# PIC32MX274F256B register map
Registers are 32-bit, access not given, reset 0x0 unless marked. A register's access mark holds for its fields unless they carry their own. Offsets are from the block's base; [hi:lo] are bit positions; 'fields as' and 'values as' point back to an identical list.

## CVR — CVR peripheral
Base 0xBF809800
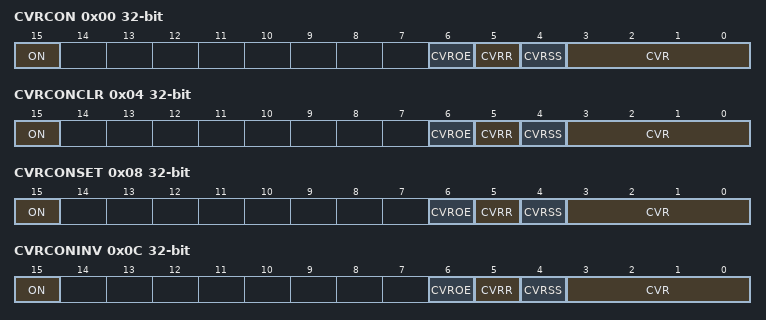
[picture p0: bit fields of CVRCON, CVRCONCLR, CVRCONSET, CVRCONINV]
0x00 CVRCON
  [15] ON, [6] CVROE, [5] CVRR, [4] CVRSS, [3:0] CVR
0x04 CVRCONCLR
  [15] ON, [6] CVROE, [5] CVRR, [4] CVRSS, [3:0] CVR
0x08 CVRCONSET
  [15] ON, [6] CVROE, [5] CVRR, [4] CVRSS, [3:0] CVR
0x0C CVRCONINV
  [15] ON, [6] CVROE, [5] CVRR, [4] CVRSS, [3:0] CVR

## CMP1 — CMP1 peripheral
Base 0xBF80A000
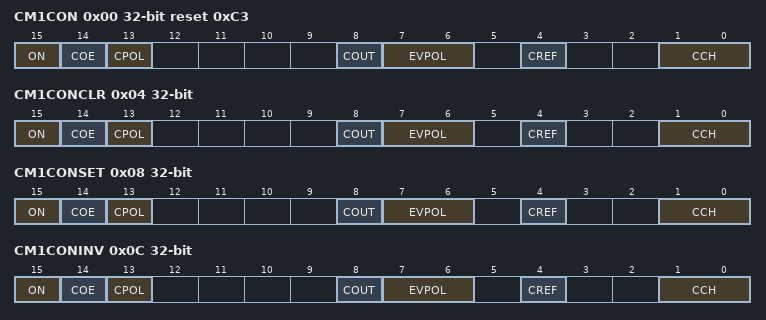
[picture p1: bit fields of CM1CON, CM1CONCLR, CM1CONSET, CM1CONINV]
0x00 CM1CON reset 0xC3
  [15] ON, [14] COE, [13] CPOL, [8] COUT, [7:6] EVPOL, [4] CREF, [1:0] CCH
0x04 CM1CONCLR
  fields as CM1CON
0x08 CM1CONSET
  fields as CM1CON
0x0C CM1CONINV
  fields as CM1CON

## CMP2 — CMP2 peripheral
Base 0xBF80A010
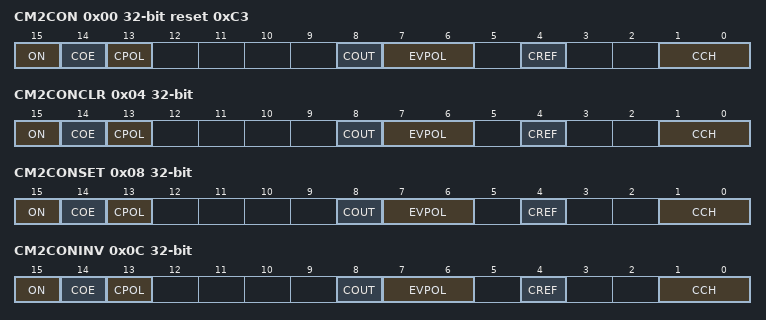
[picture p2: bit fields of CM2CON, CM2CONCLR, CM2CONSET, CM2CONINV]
0x00 CM2CON reset 0xC3
  [15] ON, [14] COE, [13] CPOL, [8] COUT, [7:6] EVPOL, [4] CREF, [1:0] CCH
0x04 CM2CONCLR
  fields as CM2CON
0x08 CM2CONSET
  fields as CM2CON
0x0C CM2CONINV
  fields as CM2CON

## CMP3 — CMP3 peripheral
Base 0xBF80A020
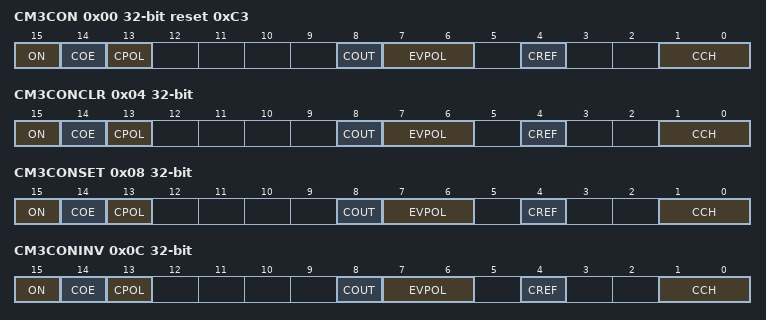
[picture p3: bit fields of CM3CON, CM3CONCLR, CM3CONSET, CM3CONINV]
0x00 CM3CON reset 0xC3
  [15] ON, [14] COE, [13] CPOL, [8] COUT, [7:6] EVPOL, [4] CREF, [1:0] CCH
0x04 CM3CONCLR
  fields as CM3CON
0x08 CM3CONSET
  fields as CM3CON
0x0C CM3CONINV
  fields as CM3CON

## CMP — CMP peripheral
Base 0xBF80A060
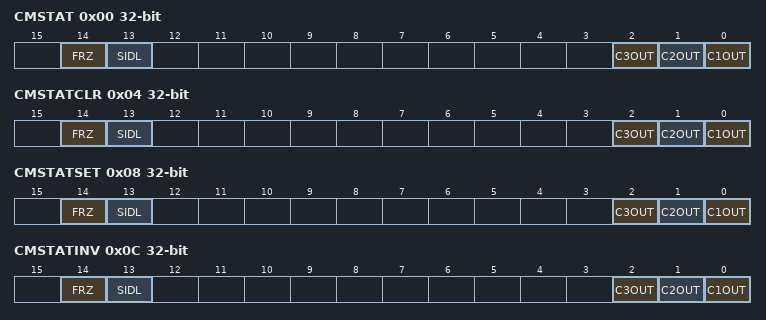
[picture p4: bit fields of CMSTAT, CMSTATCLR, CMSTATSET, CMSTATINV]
0x00 CMSTAT
  [14] FRZ, [13] SIDL, [2] C3OUT, [1] C2OUT, [0] C1OUT
0x04 CMSTATCLR
  [14] FRZ, [13] SIDL, [2] C3OUT, [1] C2OUT, [0] C1OUT
0x08 CMSTATSET
  [14] FRZ, [13] SIDL, [2] C3OUT, [1] C2OUT, [0] C1OUT
0x0C CMSTATINV
  [14] FRZ, [13] SIDL, [2] C3OUT, [1] C2OUT, [0] C1OUT

## CTMU — CTMU peripheral
Base 0xBF80A200
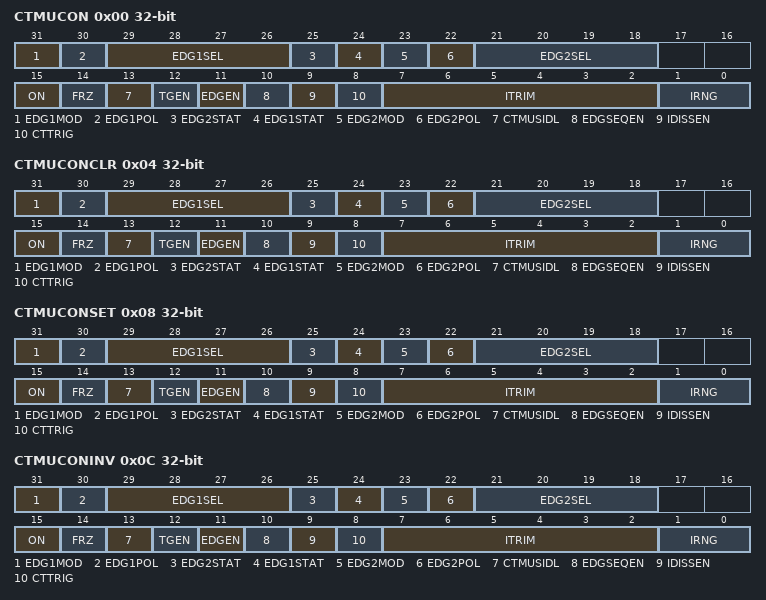
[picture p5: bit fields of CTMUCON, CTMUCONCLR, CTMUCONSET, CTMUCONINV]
0x00 CTMUCON
  [31] EDG1MOD, [30] EDG1POL, [29:26] EDG1SEL, [25] EDG2STAT, [24] EDG1STAT, [23] EDG2MOD, [22] EDG2POL, [21:18] EDG2SEL, [15] ON, [14] FRZ, [13] CTMUSIDL, [12] TGEN, [11] EDGEN, [10] EDGSEQEN, [9] IDISSEN, [8] CTTRIG, [7:2] ITRIM, [1:0] IRNG
0x04 CTMUCONCLR
  fields as CTMUCON
0x08 CTMUCONSET
  fields as CTMUCON
0x0C CTMUCONINV
  fields as CTMUCON

## CRU — CRU peripheral
Base 0xBF80F000
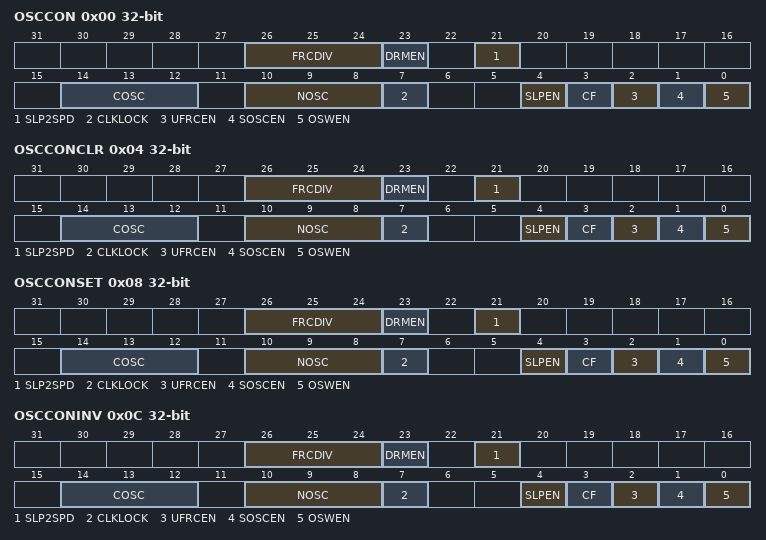
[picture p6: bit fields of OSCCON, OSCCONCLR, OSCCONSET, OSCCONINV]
0x00 OSCCON
  [26:24] FRCDIV, [23] DRMEN, [21] SLP2SPD, [14:12] COSC, [10:8] NOSC, [7] CLKLOCK, [4] SLPEN, [3] CF, [2] UFRCEN, [1] SOSCEN, [0] OSWEN
0x04 OSCCONCLR
  fields as OSCCON
0x08 OSCCONSET
  fields as OSCCON
0x0C OSCCONINV
  fields as OSCCON
0x10 OSCTUN
  [5:0] TUN
0x14 OSCTUNCLR
  [5:0] TUN
0x18 OSCTUNSET
  [5:0] TUN
0x1C OSCTUNINV
  [5:0] TUN
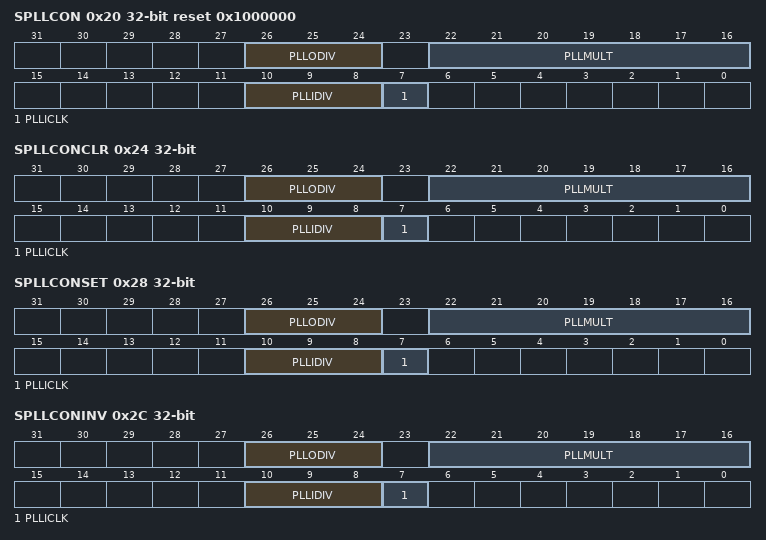
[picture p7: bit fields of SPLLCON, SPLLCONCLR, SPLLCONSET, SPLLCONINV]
0x20 SPLLCON reset 0x1000000
  [26:24] PLLODIV, [22:16] PLLMULT, [10:8] PLLIDIV, [7] PLLICLK
0x24 SPLLCONCLR
  [26:24] PLLODIV, [22:16] PLLMULT, [10:8] PLLIDIV, [7] PLLICLK
0x28 SPLLCONSET
  [26:24] PLLODIV, [22:16] PLLMULT, [10:8] PLLIDIV, [7] PLLICLK
0x2C SPLLCONINV
  [26:24] PLLODIV, [22:16] PLLMULT, [10:8] PLLIDIV, [7] PLLICLK
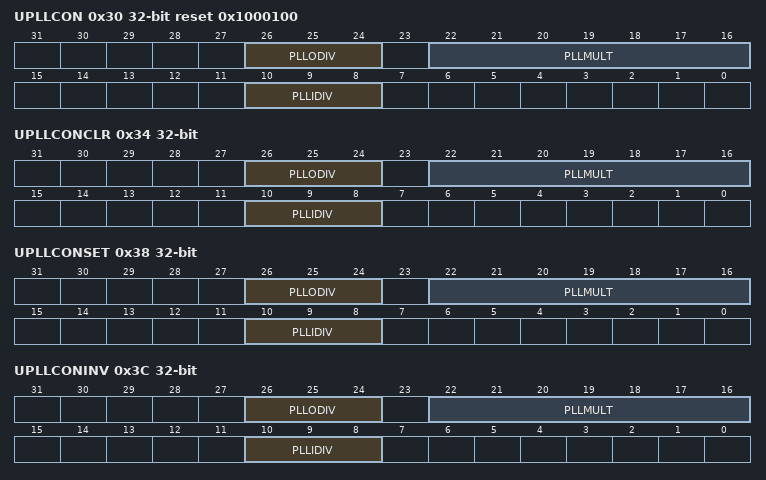
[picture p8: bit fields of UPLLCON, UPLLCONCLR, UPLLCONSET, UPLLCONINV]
0x30 UPLLCON reset 0x1000100
  [26:24] PLLODIV, [22:16] PLLMULT, [10:8] PLLIDIV
0x34 UPLLCONCLR
  [26:24] PLLODIV, [22:16] PLLMULT, [10:8] PLLIDIV
0x38 UPLLCONSET
  [26:24] PLLODIV, [22:16] PLLMULT, [10:8] PLLIDIV
0x3C UPLLCONINV
  [26:24] PLLODIV, [22:16] PLLMULT, [10:8] PLLIDIV
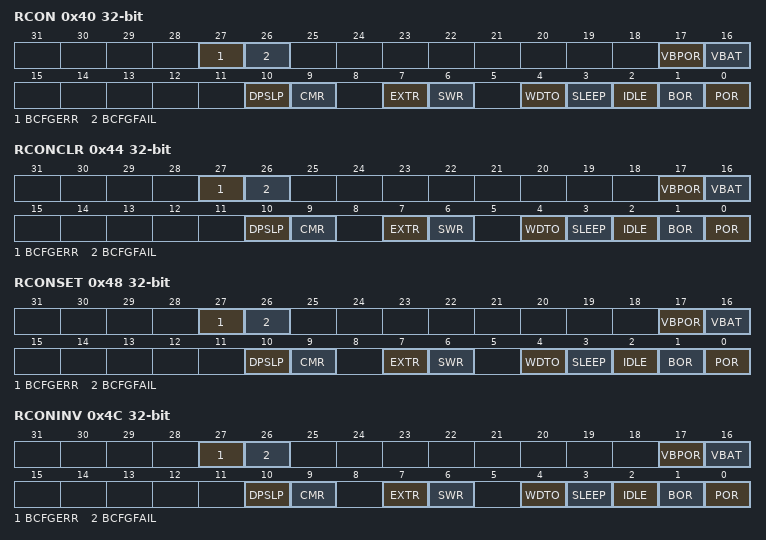
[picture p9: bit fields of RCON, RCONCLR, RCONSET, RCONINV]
0x40 RCON
  [27] BCFGERR, [26] BCFGFAIL, [17] VBPOR, [16] VBAT, [10] DPSLP, [9] CMR, [7] EXTR, [6] SWR, [4] WDTO, [3] SLEEP, [2] IDLE, [1] BOR, [0] POR
0x44 RCONCLR
  fields as RCON
0x48 RCONSET
  fields as RCON
0x4C RCONINV
  fields as RCON
0x50 RSWRST
  [0] SWRST
0x54 RSWRSTCLR
  [0] SWRST
0x58 RSWRSTSET
  [0] SWRST
0x5C RSWRSTINV
  [0] SWRST
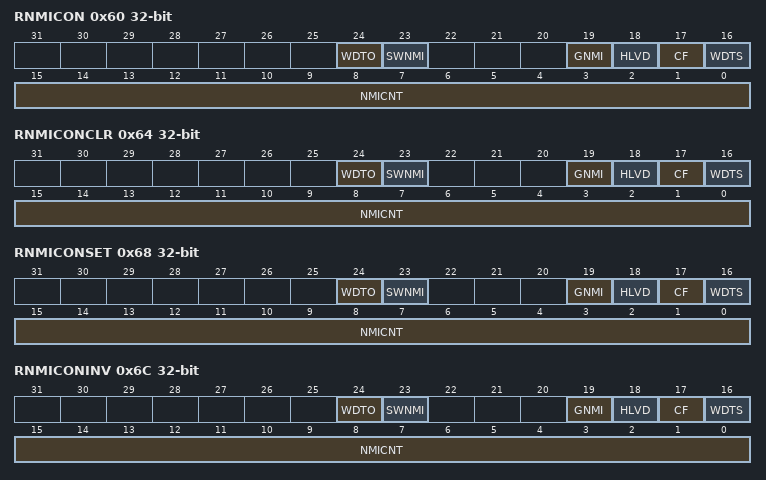
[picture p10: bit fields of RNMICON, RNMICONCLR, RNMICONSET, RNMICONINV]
0x60 RNMICON
  [24] WDTO, [23] SWNMI, [19] GNMI, [18] HLVD, [17] CF, [16] WDTS, [15:0] NMICNT
0x64 RNMICONCLR
  fields as RNMICON
0x68 RNMICONSET
  fields as RNMICON
0x6C RNMICONINV
  fields as RNMICON
0x70 PWRCON
  [0] VREGS
0x74 PWRCONCLR
  [0] VREGS
0x78 PWRCONSET
  [0] VREGS
0x7C PWRCONINV
  [0] VREGS
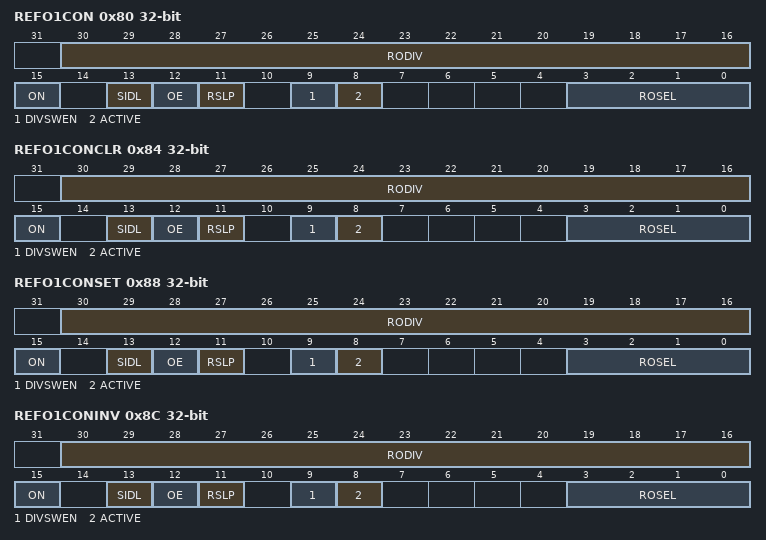
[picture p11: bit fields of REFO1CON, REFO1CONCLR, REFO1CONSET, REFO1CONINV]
0x80 REFO1CON
  [30:16] RODIV, [15] ON, [13] SIDL, [12] OE, [11] RSLP, [9] DIVSWEN, [8] ACTIVE, [3:0] ROSEL
0x84 REFO1CONCLR
  fields as REFO1CON
0x88 REFO1CONSET
  fields as REFO1CON
0x8C REFO1CONINV
  fields as REFO1CON
0x90 REFO1TRIM
  [31:23] ROTRIM
0x94 REFO1TRIMCLR
  [31:23] ROTRIM
0x98 REFO1TRIMSET
  [31:23] ROTRIM
0x9C REFO1TRIMINV
  [31:23] ROTRIM
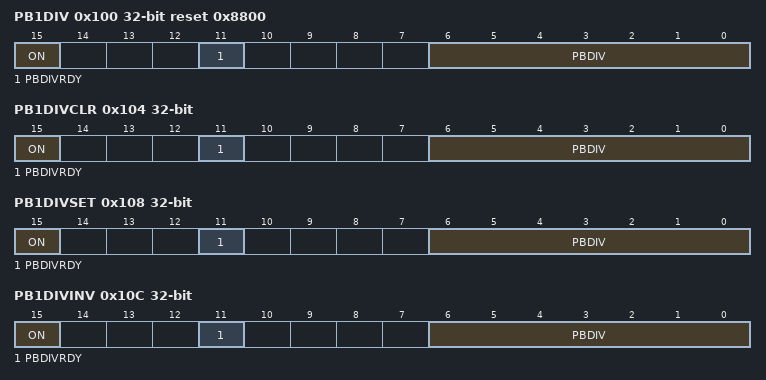
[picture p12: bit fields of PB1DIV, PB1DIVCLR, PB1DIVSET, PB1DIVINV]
0x100 PB1DIV reset 0x8800
  [15] ON, [11] PBDIVRDY, [6:0] PBDIV
0x104 PB1DIVCLR
  [15] ON, [11] PBDIVRDY, [6:0] PBDIV
0x108 PB1DIVSET
  [15] ON, [11] PBDIVRDY, [6:0] PBDIV
0x10C PB1DIVINV
  [15] ON, [11] PBDIVRDY, [6:0] PBDIV
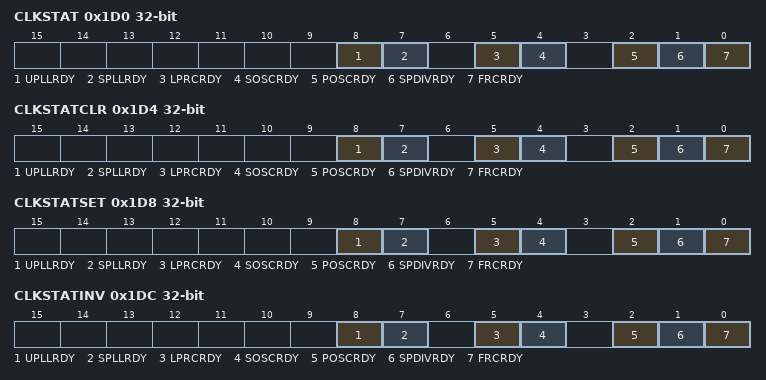
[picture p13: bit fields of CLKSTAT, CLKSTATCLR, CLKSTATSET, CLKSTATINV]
0x1D0 CLKSTAT
  [8] UPLLRDY, [7] SPLLRDY, [5] LPRCRDY, [4] SOSCRDY, [2] POSCRDY, [1] SPDIVRDY, [0] FRCRDY
0x1D4 CLKSTATCLR
  fields as CLKSTAT
0x1D8 CLKSTATSET
  fields as CLKSTAT
0x1DC CLKSTATINV
  fields as CLKSTAT
